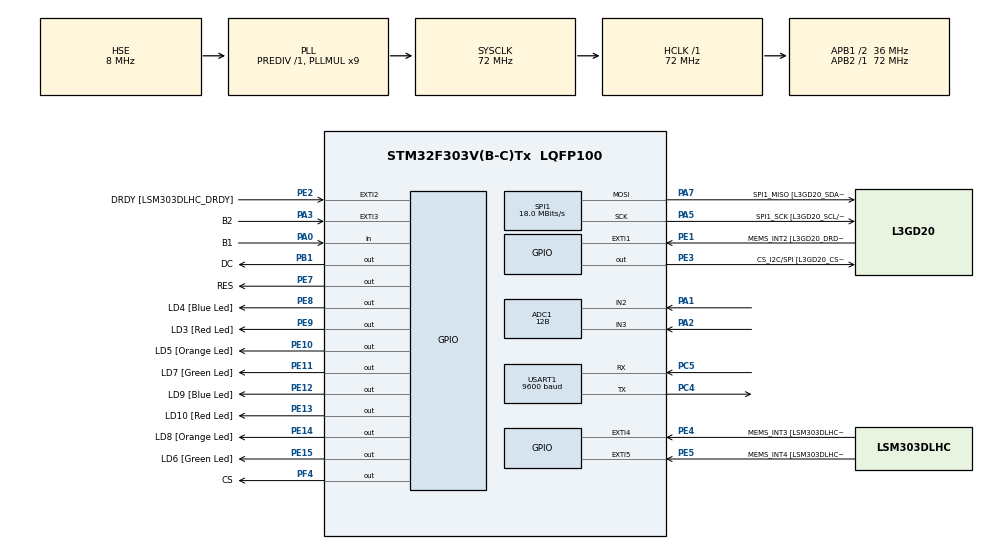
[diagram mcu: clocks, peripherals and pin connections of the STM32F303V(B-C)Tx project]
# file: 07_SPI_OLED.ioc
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ADC1.Channel-0\#ChannelRegularConversion=ADC_CHANNEL_2
ADC1.Channel-1\#ChannelRegularConversion=ADC_CHANNEL_3
ADC1.ClockPrescaler=ADC_CLOCK_ASYNC_DIV1
ADC1.ContinuousConvMode=ENABLE
ADC1.DMAContinuousRequests=ENABLE
ADC1.DataAlign=ADC_DATAALIGN_RIGHT
ADC1.DiscontinuousConvMode=DISABLE
ADC1.EOCSelection=ADC_EOC_SINGLE_CONV
ADC1.EnableAnalogWatchDog1=false
ADC1.EnableAnalogWatchDog2=false
ADC1.EnableAnalogWatchDog3=false
ADC1.EnableInjectedConversion=ENABLE
ADC1.EnableRegularConversion=ENABLE
ADC1.ExternalTrigConv=ADC_SOFTWARE_START
ADC1.ExternalTrigConvEdge=ADC_EXTERNALTRIGCONVEDGE_NONE
ADC1.InjNumberOfConversion=0
ADC1.LowPowerAutoWait=DISABLE
ADC1.NbrOfConversion=2
ADC1.NbrOfConversionFlag=1
ADC1.Offset-0\#ChannelRegularConversion=0
ADC1.Offset-1\#ChannelRegularConversion=0
ADC1.OffsetNumber-0\#ChannelRegularConversion=ADC_OFFSET_NONE
ADC1.OffsetNumber-1\#ChannelRegularConversion=ADC_OFFSET_NONE
ADC1.Overrun=ADC_OVR_DATA_OVERWRITTEN
ADC1.Rank-0\#ChannelRegularConversion=1
ADC1.Rank-1\#ChannelRegularConversion=2
ADC1.Resolution=ADC_RESOLUTION_12B
ADC1.SamplingTime-0\#ChannelRegularConversion=ADC_SAMPLETIME_181CYCLES_5
ADC1.SamplingTime-1\#ChannelRegularConversion=ADC_SAMPLETIME_181CYCLES_5
ADC1.ScanConvMode=ADC_SCAN_ENABLE
ADC1.master=1
Dma.ADC1.0.Direction=DMA_PERIPH_TO_MEMORY
Dma.ADC1.0.Instance=DMA1_Channel1
Dma.ADC1.0.MemDataAlignment=DMA_MDATAALIGN_HALFWORD
Dma.ADC1.0.MemInc=DMA_MINC_ENABLE
Dma.ADC1.0.Mode=DMA_CIRCULAR
Dma.ADC1.0.PeriphDataAlignment=DMA_PDATAALIGN_HALFWORD
Dma.ADC1.0.PeriphInc=DMA_PINC_DISABLE
Dma.ADC1.0.Priority=DMA_PRIORITY_LOW
Dma.Request0=ADC1
Mcu.Family=STM32F3
Mcu.Name=STM32F303V(B-C)Tx
Mcu.Package=LQFP100
NVIC.DMA1_Channel1_IRQn=true\:0\:0\:false\:false\:true\:false
NVIC.EXTI3_IRQn=true\:0\:0\:false\:false\:true\:true
NVIC.PriorityGroup=NVIC_PRIORITYGROUP_0
NVIC.TIM1_UP_TIM16_IRQn=true\:0\:0\:false\:false\:true\:true
NVIC.USART1_IRQn=true\:0\:0\:false\:false\:true\:true
PA0.GPIO_Label=B1
PA0.Signal=GPIO_Input
PA1.Mode=IN2-Single-Ended
PA1.Signal=ADC1_IN2
PA11.GPIO_Label=DM
PA11.Signal=USB_DM
PA12.GPIO_Label=DP
PA12.Signal=USB_DP
PA13.GPIO_Label=SWDIO
PA13.Signal=SYS_JTMS-SWDIO
PA14.GPIO_Label=SWCLK
PA14.Signal=SYS_JTCK-SWCLK
PA2.Mode=IN3-Single-Ended
PA2.Signal=ADC1_IN3
PA3.GPIO_Label=B2
PA3.GPIO_ModeDefaultEXTI=GPIO_MODE_IT_RISING_FALLING
PA3.GPIO_PuPd=GPIO_PULLUP
PA3.Signal=GPXTI3
PA5.GPIO_Label=SPI1_SCK [L3GD20_SCL/SPC]
PA5.GPIO_Mode=GPIO_MODE_AF_PP
PA5.GPIO_PuPd=GPIO_NOPULL
PA5.GPIO_Speed=GPIO_SPEED_FREQ_LOW
PA5.Mode=TX_Only_Simplex_Unidirect_Master
PA5.Signal=SPI1_SCK
PA6.GPIO_Label=SPI1_MISO [L3GD20_SA0/SDO]
PA6.GPIO_Mode=GPIO_MODE_AF_PP
PA6.GPIO_PuPd=GPIO_NOPULL
PA6.GPIO_Speed=GPIO_SPEED_FREQ_LOW
PA6.Signal=SPI1_MISO
PA7.GPIO_Label=SPI1_MISO [L3GD20_SDA/SDI/SDO]
PA7.GPIO_Mode=GPIO_MODE_AF_PP
PA7.GPIO_PuPd=GPIO_NOPULL
PA7.GPIO_Speed=GPIO_SPEED_FREQ_LOW
PA7.Mode=TX_Only_Simplex_Unidirect_Master
PA7.Signal=SPI1_MOSI
PB1.GPIO_Label=DC
PB1.Signal=GPIO_Output
PB3.GPIO_Label=SWO
PB3.Signal=SYS_JTDO-TRACESWO
PB6.GPIO_FM6=__NULL
PB6.GPIO_Label=I2C1_SCL [LSM303DLHC_SCL]
PB6.GPIO_Mode=GPIO_MODE_AF_OD
PB6.GPIO_PuPd=GPIO_NOPULL
PB6.GPIO_Speed=GPIO_SPEED_FREQ_LOW
PB6.Signal=I2C1_SCL
PB7.GPIO_FM7=__NULL
PB7.GPIO_Label=I2C1_SDA [LSM303DLHC_SDA]
PB7.GPIO_Mode=GPIO_MODE_AF_OD
PB7.GPIO_PuPd=GPIO_NOPULL
PB7.GPIO_Speed=GPIO_SPEED_FREQ_LOW
PB7.Signal=I2C1_SDA
PC14-OSC32_IN.GPIO_Label=OSC32_IN
PC14-OSC32_IN.Signal=RCC_OSC32_IN
PC15-OSC32_OUT.GPIO_Label=OSC32_OUT
PC15-OSC32_OUT.Signal=RCC_OSC32_OUT
PC4.GPIO_PuPd=GPIO_PULLUP
PC4.Mode=Asynchronous
PC4.Signal=USART1_TX
PC5.GPIO_PuPd=GPIO_PULLUP
PC5.Mode=Asynchronous
PC5.Signal=USART1_RX
PD6.Signal=USART2_RX
PE1.GPIO_Label=MEMS_INT2 [L3GD20_DRDY/INT2]
PE1.GPIO_ModeDefaultEXTI=GPIO_MODE_EVT_RISING
PE1.GPIO_PuPd=GPIO_NOPULL
PE1.Signal=GPXTI1
PE10.GPIO_Label=LD5 [Orange Led]
PE10.GPIO_ModeDefaultOutputPP=GPIO_MODE_OUTPUT_PP
PE10.GPIO_PuPd=GPIO_NOPULL
PE10.GPIO_Speed=GPIO_SPEED_FREQ_LOW
PE10.Signal=GPIO_Output
PE11.GPIO_Label=LD7 [Green Led]
PE11.GPIO_ModeDefaultOutputPP=GPIO_MODE_OUTPUT_PP
PE11.GPIO_PuPd=GPIO_NOPULL
PE11.GPIO_Speed=GPIO_SPEED_FREQ_LOW
PE11.Signal=GPIO_Output
PE12.GPIO_Label=LD9 [Blue Led]
PE12.GPIO_ModeDefaultOutputPP=GPIO_MODE_OUTPUT_PP
PE12.GPIO_PuPd=GPIO_NOPULL
PE12.GPIO_Speed=GPIO_SPEED_FREQ_LOW
PE12.Signal=GPIO_Output
PE13.GPIO_Label=LD10 [Red Led]
PE13.GPIO_ModeDefaultOutputPP=GPIO_MODE_OUTPUT_PP
PE13.GPIO_PuPd=GPIO_NOPULL
PE13.GPIO_Speed=GPIO_SPEED_FREQ_LOW
PE13.Signal=GPIO_Output
PE14.GPIO_Label=LD8 [Orange Led]
PE14.GPIO_ModeDefaultOutputPP=GPIO_MODE_OUTPUT_PP
PE14.GPIO_PuPd=GPIO_NOPULL
PE14.GPIO_Speed=GPIO_SPEED_FREQ_LOW
PE14.Signal=GPIO_Output
PE15.GPIO_Label=LD6 [Green Led]
PE15.GPIO_ModeDefaultOutputPP=GPIO_MODE_OUTPUT_PP
PE15.GPIO_PuPd=GPIO_NOPULL
PE15.GPIO_Speed=GPIO_SPEED_FREQ_LOW
PE15.Signal=GPIO_Output
PE2.GPIO_Label=DRDY [LSM303DLHC_DRDY]
PE2.GPIO_ModeDefaultEXTI=GPIO_MODE_EVT_RISING
PE2.GPIO_PuPd=GPIO_NOPULL
PE2.Signal=GPXTI2
PE3.GPIO_Label=CS_I2C/SPI [L3GD20_CS_I2C/SPI]
PE3.GPIO_ModeDefaultOutputPP=GPIO_MODE_OUTPUT_PP
PE3.GPIO_PuPd=GPIO_NOPULL
PE3.GPIO_Speed=GPIO_SPEED_FREQ_LOW
PE3.Signal=GPIO_Output
PE4.GPIO_Label=MEMS_INT3 [LSM303DLHC_INT1]
PE4.GPIO_ModeDefaultEXTI=GPIO_MODE_EVT_RISING
PE4.GPIO_PuPd=GPIO_NOPULL
PE4.Signal=GPXTI4
PE5.GPIO_Label=MEMS_INT4 [LSM303DLHC_INT2]
PE5.GPIO_ModeDefaultEXTI=GPIO_MODE_EVT_RISING
PE5.GPIO_PuPd=GPIO_NOPULL
PE5.Signal=GPXTI5
PE7.GPIO_Label=RES
PE7.Signal=GPIO_Output
PE8.GPIO_Label=LD4 [Blue Led]
PE8.GPIO_ModeDefaultOutputPP=GPIO_MODE_OUTPUT_PP
PE8.GPIO_PuPd=GPIO_NOPULL
PE8.GPIO_Speed=GPIO_SPEED_FREQ_LOW
PE8.Signal=GPIO_Output
PE9.GPIO_Label=LD3 [Red Led]
PE9.GPIO_ModeDefaultOutputPP=GPIO_MODE_OUTPUT_PP
PE9.GPIO_PuPd=GPIO_NOPULL
PE9.GPIO_Speed=GPIO_SPEED_FREQ_LOW
PE9.Signal=GPIO_Output
PF0-OSC_IN.GPIO_Label=OSC_IN
PF0-OSC_IN.Mode=HSE-External-Oscillator
PF0-OSC_IN.Signal=RCC_OSC_IN
PF1-OSC_OUT.GPIO_Label=OSC_OUT
PF1-OSC_OUT.Mode=HSE-External-Oscillator
PF1-OSC_OUT.Signal=RCC_OSC_OUT
PF4.GPIO_Label=CS
PF4.Signal=GPIO_Output
ProjectManager.HeapSize=0x200
ProjectManager.StackSize=0x400
ProjectManager.TargetToolchain=SW4STM32
RCC.AHBFreq_Value=72000000
RCC.APB1CLKDivider=RCC_HCLK_DIV2
RCC.APB1Freq_Value=36000000
RCC.APB1TimFreq_Value=72000000
RCC.APB2Freq_Value=72000000
RCC.APB2TimFreq_Value=72000000
RCC.CortexFreq_Value=72000000
RCC.HCLKFreq_Value=72000000
RCC.HSE_VALUE=8000000
RCC.HSI_VALUE=8000000
RCC.LSE_VALUE=32768
RCC.PLLMUL=RCC_PLL_MUL9
RCC.PLLSourceVirtual=RCC_PLLSOURCE_HSE
RCC.SYSCLKFreq_VALUE=72000000
RCC.SYSCLKSourceVirtual=RCC_SYSCLKSOURCE_PLLCLK
RCC.USBFreq_Value=72000000
SPI1.BaudRatePrescaler=SPI_BAUDRATEPRESCALER_4
SPI1.CLKPhase=SPI_PHASE_2EDGE
SPI1.CLKPolarity=SPI_POLARITY_HIGH
SPI1.CalculateBaudRate=18.0 MBits/s
SPI1.DataSize=SPI_DATASIZE_8BIT
SPI1.Direction=SPI_DIRECTION_2LINES
SPI1.Mode=SPI_MODE_MASTER
SPI1.VirtualType=VM_MASTER
TIM16.Period=3599
TIM16.Prescaler=9999
USART1.BaudRate=9600
USART1.VirtualMode-Asynchronous=VM_ASYNC
VP_TIM16_VS_ClockSourceINT.Mode=Enable_Timer
board=STM32F3DISCOVERY

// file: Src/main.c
/**
 ******************************************************************************
 * @file           : main.c
 * @brief          : Main program body
 ******************************************************************************
 ** This notice applies to any and all portions of this file
 * that are not between comment pairs USER CODE BEGIN and
 * USER CODE END. Other portions of this file, whether
 * inserted by the user or by software development tools
 * are owned by their respective copyright owners.
 *
 * COPYRIGHT(c) 2019 STMicroelectronics
 *
 * Redistribution and use in source and binary forms, with or without modification,
 * are permitted provided that the following conditions are met:
 *   1. Redistributions of source code must retain the above copyright notice,
 *      this list of conditions and the following disclaimer.
 *   2. Redistributions in binary form must reproduce the above copyright notice,
 *      this list of conditions and the following disclaimer in the documentation
 *      and/or other materials provided with the distribution.
 *   3. Neither the name of STMicroelectronics nor the names of its contributors
 *      may be used to endorse or promote products derived from this software
 *      without specific prior written permission.
 *
 * THIS SOFTWARE IS PROVIDED BY THE COPYRIGHT HOLDERS AND CONTRIBUTORS "AS IS"
 * AND ANY EXPRESS OR IMPLIED WARRANTIES, INCLUDING, BUT NOT LIMITED TO, THE
 * IMPLIED WARRANTIES OF MERCHANTABILITY AND FITNESS FOR A PARTICULAR PURPOSE ARE
 * DISCLAIMED. IN NO EVENT SHALL THE COPYRIGHT HOLDER OR CONTRIBUTORS BE LIABLE
 * FOR ANY DIRECT, INDIRECT, INCIDENTAL, SPECIAL, EXEMPLARY, OR CONSEQUENTIAL
 * DAMAGES (INCLUDING, BUT NOT LIMITED TO, PROCUREMENT OF SUBSTITUTE GOODS OR
 * SERVICES; LOSS OF USE, DATA, OR PROFITS; OR BUSINESS INTERRUPTION) HOWEVER
 * CAUSED AND ON ANY THEORY OF LIABILITY, WHETHER IN CONTRACT, STRICT LIABILITY,
 * OR TORT (INCLUDING NEGLIGENCE OR OTHERWISE) ARISING IN ANY WAY OUT OF THE USE
 * OF THIS SOFTWARE, EVEN IF ADVISED OF THE POSSIBILITY OF SUCH DAMAGE.
 *
 ******************************************************************************
 */
#include "main.h"
#include "stm32f3xx_hal.h"

/* USER CODE BEGIN Includes */
#include "SSD1331.h"

/* USER CODE END Includes */

ADC_HandleTypeDef hadc1;
DMA_HandleTypeDef hdma_adc1;

SPI_HandleTypeDef hspi1;

TIM_HandleTypeDef htim16;

UART_HandleTypeDef huart1;

/* USER CODE BEGIN PV */
/* Private variables ---------------------------------------------------------*/
volatile uint16_t Joystick[2];
uint8_t field[9];
uint8_t i;
uint8_t player = 0;
uint8_t win = 0;
uint8_t draw = 0;
uint8_t cursor = 0;
uint8_t move = 0;
uint8_t error = 0;
uint8_t scoreX = 0;
uint8_t scoreO = 0;
uint8_t Received;
uint8_t buffer[20];
uint8_t data[300]; // Tablica przechowujaca wysylana wiadomosc.
uint16_t size = 0; // Rozmiar wysylanej wiadomosci
/* USER CODE END PV */

void SystemClock_Config(void);
static void MX_GPIO_Init(void);
static void MX_DMA_Init(void);
static void MX_SPI1_Init(void);
static void MX_ADC1_Init(void);
static void MX_USART1_UART_Init(void);
static void MX_TIM16_Init(void);

/* USER CODE BEGIN PFP */
/* Private function prototypes -----------------------------------------------*/

static void drawOnScreen(bool gameInProgress) {
	uint16_t size = 0;
	char fieldChar[9];
	char currentPlayer;

	for (uint8_t i = 0; i < 9; i++) {
		if (field[i] == 0) {
			fieldChar[i] = 'X';
		} else if (field[i] == 1) {
			fieldChar[i] = 'O';
		} else if (field[i] == 2) {
			fieldChar[i] = ' ';
		} else {
			fieldChar[i] = ' ';
		}
	}

	if (player == 0 && gameInProgress == false) {
		currentPlayer = 'X';
	} else if (player == 1 && gameInProgress == false) {
		currentPlayer = 'O';
	} else if (player == 1 && gameInProgress == true) {
		currentPlayer = 'X';
	} else if (player == 0 && gameInProgress == true) {
		currentPlayer = 'O';
	}

	if (win == 1 && player == 0) {
		size =
				sprintf(data,
						"\n\r%c|%c|%c\n\r-+-+-\n\r%c|%c|%c\n\r-+-+-\n\r%c|%c|%c\n\r\n\r\n\r\x1b[31mGracz X wygral!\n\r",
						fieldChar[0], fieldChar[1], fieldChar[2], fieldChar[3],
						fieldChar[4], fieldChar[5], fieldChar[6], fieldChar[7],
						fieldChar[8], currentPlayer);
	} else if (win == 1 && player == 1) {
		size =
				sprintf(data,
						"\n\r%c|%c|%c\n\r-+-+-\n\r%c|%c|%c\n\r-+-+-\n\r%c|%c|%c\n\r\n\r\n\r\x1b[32mGracz O wygral!\n\r",
						fieldChar[0], fieldChar[1], fieldChar[2], fieldChar[3],
						fieldChar[4], fieldChar[5], fieldChar[6], fieldChar[7],
						fieldChar[8], currentPlayer);
	} else if (draw == 1) {
		size =
				sprintf(data,
						"\n\r%c|%c|%c\n\r-+-+-\n\r%c|%c|%c\n\r-+-+-\n\r%c|%c|%c\n\r\n\r\n\r\x1b[34mRemis!\n\r",
						fieldChar[0], fieldChar[1], fieldChar[2], fieldChar[3],
						fieldChar[4], fieldChar[5], fieldChar[6], fieldChar[7],
						fieldChar[8], currentPlayer);
	} else if (currentPlayer == 'X' && cursor == 0) {
		size =
				sprintf(data,
						"\n\r\x1b[31m%c|\x1b[0m%c|%c\n\r\x1b[31m-+\x1b[0m-+-\n\r%c|%c|%c\n\r-+-+-\n\r%c|%c|%c\n\r\n\r\x1b[31m\x1b[31mTura gracza %c!\n\r\x1b[0m\n\r",
						fieldChar[0], fieldChar[1], fieldChar[2], fieldChar[3],
						fieldChar[4], fieldChar[5], fieldChar[6], fieldChar[7],
						fieldChar[8], currentPlayer);
	} else if (currentPlayer == 'O' && cursor == 0) {
		size =
				sprintf(data,
						"\n\r\x1b[32m%c|\x1b[0m%c|%c\n\r\x1b[32m-+\x1b[0m-+-\n\r%c|%c|%c\n\r-+-+-\n\r%c|%c|%c\n\r\n\r\x1b[31m\x1b[32mTura gracza %c!\n\r\x1b[0m\n\r",
						fieldChar[0], fieldChar[1], fieldChar[2], fieldChar[3],
						fieldChar[4], fieldChar[5], fieldChar[6], fieldChar[7],
						fieldChar[8], currentPlayer);
	} else if (currentPlayer == 'X' && cursor == 1) {
		size =
				sprintf(data,
						"\x1b[0m\n\r%c\x1b[31m|%c|\x1b[0m%c\n\r-\x1b[31m+-+\x1b[0m-\n\r%c|%c|%c\n\r-+-+-\n\r%c|%c|%c\n\r\n\r\x1b[31mTura gracza %c!\n\r\x1b[0m\n\r",
						fieldChar[0], fieldChar[1], fieldChar[2], fieldChar[3],
						fieldChar[4], fieldChar[5], fieldChar[6], fieldChar[7],
						fieldChar[8], currentPlayer);
	} else if (currentPlayer == 'O' && cursor == 1) {
		size =
				sprintf(data,
						"\x1b[0m\n\r%c\x1b[32m|%c|\x1b[0m%c\n\r-\x1b[32m+-+\x1b[0m-\n\r%c|%c|%c\n\r-+-+-\n\r%c|%c|%c\n\r\n\r\x1b[32mTura gracza %c!\n\r\x1b[0m\n\r",
						fieldChar[0], fieldChar[1], fieldChar[2], fieldChar[3],
						fieldChar[4], fieldChar[5], fieldChar[6], fieldChar[7],
						fieldChar[8], currentPlayer);
	} else if (currentPlayer == 'X' && cursor == 2) {
		size =
				sprintf(data,
						"\x1b[0m\n\r%c|%c\x1b[31m|%c\x1b[0m\n\r-+-\x1b[31m+-\x1b[0m\n\r%c|%c|%c\n\r-+-+-\n\r%c|%c|%c\n\r\n\r\x1b[31mTura gracza %c!\n\r\x1b[0m\n\r",
						fieldChar[0], fieldChar[1], fieldChar[2], fieldChar[3],
						fieldChar[4], fieldChar[5], fieldChar[6], fieldChar[7],
						fieldChar[8], currentPlayer);
	} else if (currentPlayer == 'O' && cursor == 2) {
		size =
				sprintf(data,
						"\x1b[0m\n\r%c|%c\x1b[32m|%c\x1b[0m\n\r-+-\x1b[32m+-\x1b[0m\n\r%c|%c|%c\n\r-+-+-\n\r%c|%c|%c\n\r\n\r\x1b[32mTura gracza %c!\n\r\x1b[0m\n\r",
						fieldChar[0], fieldChar[1], fieldChar[2], fieldChar[3],
						fieldChar[4], fieldChar[5], fieldChar[6], fieldChar[7],
						fieldChar[8], currentPlayer);
	} else if (currentPlayer == 'X' && cursor == 3) {
		size =
				sprintf(data,
						"\x1b[0m\n\r%c|%c|%c\n\r\x1b[31m-+\x1b[0m-+-\n\r\x1b[31m%c|\x1b[0m%c|%c\n\r\x1b[31m-+\x1b[0m-+-\n\r%c|%c|%c\n\r\n\r\x1b[31mTura gracza %c!\n\r\x1b[0m\n\r",
						fieldChar[0], fieldChar[1], fieldChar[2], fieldChar[3],
						fieldChar[4], fieldChar[5], fieldChar[6], fieldChar[7],
						fieldChar[8], currentPlayer);
	} else if (currentPlayer == 'O' && cursor == 3) {
		size =
				sprintf(data,
						"\x1b[0m\n\r%c|%c|%c\n\r\x1b[32m-+\x1b[0m-+-\n\r\x1b[32m%c|\x1b[0m%c|%c\n\r\x1b[32m-+\x1b[0m-+-\n\r%c|%c|%c\n\r\n\r\x1b[32mTura gracza %c!\n\r\x1b[0m\n\r",
						fieldChar[0], fieldChar[1], fieldChar[2], fieldChar[3],
						fieldChar[4], fieldChar[5], fieldChar[6], fieldChar[7],
						fieldChar[8], currentPlayer);
	} else if (currentPlayer == 'X' && cursor == 4) {
		size =
				sprintf(data,
						"\x1b[0m\n\r%c|%c|%c\n\r-\x1b[31m+-+\x1b[0m-\n\r%c\x1b[31m|%c|\x1b[0m%c\n\r-\x1b[31m+-+\x1b[0m-\n\r%c|%c|%c\n\r\n\r\x1b[31mTura gracza %c!\n\r\x1b[0m\n\r",
						fieldChar[0], fieldChar[1], fieldChar[2], fieldChar[3],
						fieldChar[4], fieldChar[5], fieldChar[6], fieldChar[7],
						fieldChar[8], currentPlayer);
	} else if (currentPlayer == 'O' && cursor == 4) {
		size =
				sprintf(data,
						"\x1b[0m\n\r%c|%c|%c\n\r-\x1b[32m+-+\x1b[0m-\n\r%c\x1b[32m|%c|\x1b[0m%c\n\r-\x1b[32m+-+\x1b[0m-\n\r%c|%c|%c\n\r\n\r\x1b[32mTura gracza %c!\n\r\x1b[0m\n\r",
						fieldChar[0], fieldChar[1], fieldChar[2], fieldChar[3],
						fieldChar[4], fieldChar[5], fieldChar[6], fieldChar[7],
						fieldChar[8], currentPlayer);

	} else if (currentPlayer == 'X' && cursor == 5) {
		size =
				sprintf(data,
						"\x1b[0m\n\r%c|%c|%c\n\r-+-\x1b[31m+-\x1b[0m\n\r%c|%c\x1b[31m|%c\x1b[0m\n\r-+-\x1b[31m+-\x1b[0m\n\r%c|%c|%c\n\r\n\r\x1b[31mTura gracza %c!\n\r\x1b[0m\n\r",
						fieldChar[0], fieldChar[1], fieldChar[2], fieldChar[3],
						fieldChar[4], fieldChar[5], fieldChar[6], fieldChar[7],
						fieldChar[8], currentPlayer);
	} else if (currentPlayer == 'O' && cursor == 5) {
		size =
				sprintf(data,
						"\x1b[0m\n\r%c|%c|%c\n\r-+-\x1b[32m+-\x1b[0m\n\r%c|%c\x1b[32m|%c\x1b[0m\n\r-+-\x1b[32m+-\x1b[0m\n\r%c|%c|%c\n\r\n\r\x1b[32mTura gracza %c!\n\r\x1b[0m\n\r",
						fieldChar[0], fieldChar[1], fieldChar[2], fieldChar[3],
						fieldChar[4], fieldChar[5], fieldChar[6], fieldChar[7],
						fieldChar[8], currentPlayer);

	} else if (currentPlayer == 'X' && cursor == 6) {
		size =
				sprintf(data,
						"\x1b[0m\n\r%c|%c|%c\n\r-+-+-\n\r%c|%c|%c\n\r\x1b[31m-+\x1b[0m-+-\n\r\x1b[31m%c|\x1b[0m%c|%c\n\r\n\r\x1b[31mTura gracza %c!\n\r\x1b[0m\n\r",
						fieldChar[0], fieldChar[1], fieldChar[2], fieldChar[3],
						fieldChar[4], fieldChar[5], fieldChar[6], fieldChar[7],
						fieldChar[8], currentPlayer);
	} else if (currentPlayer == 'O' && cursor == 6) {
		size =
				sprintf(data,
						"\x1b[0m\n\r%c|%c|%c\n\r-+-+-\n\r%c|%c|%c\n\r\x1b[32m-+\x1b[0m-+-\n\r\x1b[32m%c|\x1b[0m%c|%c\n\r\n\r\x1b[32mTura gracza %c!\n\r\x1b[0m\n\r",
						fieldChar[0], fieldChar[1], fieldChar[2], fieldChar[3],
						fieldChar[4], fieldChar[5], fieldChar[6], fieldChar[7],
						fieldChar[8], currentPlayer);

	} else if (currentPlayer == 'X' && cursor == 7) {
		size =
				sprintf(data,
						"\x1b[0m\n\r%c|%c|%c\n\r-+-+-\n\r%c|%c|%c\n\r-\x1b[31m+-+\x1b[0m-\n\r%c\x1b[31m|%c|\x1b[0m%c\n\r\n\r\x1b[31mTura gracza %c!\n\r\x1b[0m\n\r",
						fieldChar[0], fieldChar[1], fieldChar[2], fieldChar[3],
						fieldChar[4], fieldChar[5], fieldChar[6], fieldChar[7],
						fieldChar[8], currentPlayer);
	} else if (currentPlayer == 'O' && cursor == 7) {
		size =
				sprintf(data,
						"\x1b[0m\n\r%c|%c|%c\n\r-+-+-\n\r%c|%c|%c\n\r-\x1b[32m+-+\x1b[0m-\n\r%c\x1b[32m|%c|\x1b[0m%c\n\r\n\r\x1b[32mTura gracza %c!\n\r\x1b[0m\n\r",
						fieldChar[0], fieldChar[1], fieldChar[2], fieldChar[3],
						fieldChar[4], fieldChar[5], fieldChar[6], fieldChar[7],
						fieldChar[8], currentPlayer);

	} else if (currentPlayer == 'X' && cursor == 8) {
		size =
				sprintf(data,
						"\x1b[0m\n\r%c|%c|%c\n\r-+-+-\n\r%c|%c|%c\n\r-+-\x1b[31m+-\x1b[0m\n\r%c|%c\x1b[31m|%c\x1b[0m\n\r\n\r\x1b[31mTura gracza %c!\n\r\x1b[0m\n\r",
						fieldChar[0], fieldChar[1], fieldChar[2], fieldChar[3],
						fieldChar[4], fieldChar[5], fieldChar[6], fieldChar[7],
						fieldChar[8], currentPlayer);
	} else if (currentPlayer == 'O' && cursor == 8) {
		size =
				sprintf(data,
						"\x1b[0m\n\r%c|%c|%c\n\r-+-+-\n\r%c|%c|%c\n\r-+-\x1b[32m+-\x1b[0m\n\r%c|%c\x1b[32m|%c\x1b[0m\n\r\n\r\x1b[32mTura gracza %c!\n\r\x1b[0m\n\r",
						fieldChar[0], fieldChar[1], fieldChar[2], fieldChar[3],
						fieldChar[4], fieldChar[5], fieldChar[6], fieldChar[7],
						fieldChar[8], currentPlayer);

	}
	HAL_UART_Transmit_IT(&huart1, data, size); // Rozpoczecie nadawania danych z wykorzystaniem przerwan
	HAL_GPIO_TogglePin(LD7_GPIO_Port, LD7_Pin); // Zmiana stanu pinu na diodzie LED

}

static void drawOnMove(bool gameInProgress) {
	uint16_t size = 0;
	char fieldChar[9];
	char currentPlayer;

	for (uint8_t i = 0; i < 9; i++) {
		if (field[i] == 0) {
			fieldChar[i] = 'X';
		} else if (field[i] == 1) {
			fieldChar[i] = 'O';
		} else if (field[i] == 2) {
			fieldChar[i] = ' ';
		} else {
			fieldChar[i] = ' ';
		}
	}

	if (player == 0 && gameInProgress == false) {
		currentPlayer = 'X';
	} else if (player == 1 && gameInProgress == false) {
		currentPlayer = 'O';
	} else if (player == 1 && gameInProgress == true) {
		currentPlayer = 'X';
	} else if (player == 0 && gameInProgress == true) {
		currentPlayer = 'O';
	}

	if (currentPlayer == 'X' && cursor == 0) {
		size =
				sprintf(data,
						"\n\r\x1b[31m%c|\x1b[0m%c|%c\n\r\x1b[31m-+\x1b[0m-+-\n\r%c|%c|%c\n\r-+-+-\n\r%c|%c|%c\n\r\n\r\x1b[31m\x1b[31mTura gracza %c!\n\r\x1b[0m\n\r",
						fieldChar[0], fieldChar[1], fieldChar[2], fieldChar[3],
						fieldChar[4], fieldChar[5], fieldChar[6], fieldChar[7],
						fieldChar[8], currentPlayer);
	} else if (currentPlayer == 'O' && cursor == 0) {
		size =
				sprintf(data,
						"\n\r\x1b[32m%c|\x1b[0m%c|%c\n\r\x1b[32m-+\x1b[0m-+-\n\r%c|%c|%c\n\r-+-+-\n\r%c|%c|%c\n\r\n\r\x1b[31m\x1b[32mTura gracza %c!\n\r\x1b[0m\n\r",
						fieldChar[0], fieldChar[1], fieldChar[2], fieldChar[3],
						fieldChar[4], fieldChar[5], fieldChar[6], fieldChar[7],
						fieldChar[8], currentPlayer);
	} else if (currentPlayer == 'X' && cursor == 1) {
		size =
				sprintf(data,
						"\x1b[0m\n\r%c\x1b[31m|%c|\x1b[0m%c\n\r-\x1b[31m+-+\x1b[0m-\n\r%c|%c|%c\n\r-+-+-\n\r%c|%c|%c\n\r\n\r\x1b[31mTura gracza %c!\n\r\x1b[0m\n\r",
						fieldChar[0], fieldChar[1], fieldChar[2], fieldChar[3],
						fieldChar[4], fieldChar[5], fieldChar[6], fieldChar[7],
						fieldChar[8], currentPlayer);
	} else if (currentPlayer == 'O' && cursor == 1) {
		size =
				sprintf(data,
						"\x1b[0m\n\r%c\x1b[32m|%c|\x1b[0m%c\n\r-\x1b[32m+-+\x1b[0m-\n\r%c|%c|%c\n\r-+-+-\n\r%c|%c|%c\n\r\n\r\x1b[32mTura gracza %c!\n\r\x1b[0m\n\r",
						fieldChar[0], fieldChar[1], fieldChar[2], fieldChar[3],
						fieldChar[4], fieldChar[5], fieldChar[6], fieldChar[7],
						fieldChar[8], currentPlayer);
	} else if (currentPlayer == 'X' && cursor == 2) {
		size =
				sprintf(data,
						"\x1b[0m\n\r%c|%c\x1b[31m|%c\x1b[0m\n\r-+-\x1b[31m+-\x1b[0m\n\r%c|%c|%c\n\r-+-+-\n\r%c|%c|%c\n\r\n\r\x1b[31mTura gracza %c!\n\r\x1b[0m\n\r",
						fieldChar[0], fieldChar[1], fieldChar[2], fieldChar[3],
						fieldChar[4], fieldChar[5], fieldChar[6], fieldChar[7],
						fieldChar[8], currentPlayer);
	} else if (currentPlayer == 'O' && cursor == 2) {
		size =
				sprintf(data,
						"\x1b[0m\n\r%c|%c\x1b[32m|%c\x1b[0m\n\r-+-\x1b[32m+-\x1b[0m\n\r%c|%c|%c\n\r-+-+-\n\r%c|%c|%c\n\r\n\r\x1b[32mTura gracza %c!\n\r\x1b[0m\n\r",
						fieldChar[0], fieldChar[1], fieldChar[2], fieldChar[3],
						fieldChar[4], fieldChar[5], fieldChar[6], fieldChar[7],
						fieldChar[8], currentPlayer);
	} else if (currentPlayer == 'X' && cursor == 3) {
		size =
				sprintf(data,
						"\x1b[0m\n\r%c|%c|%c\n\r\x1b[31m-+\x1b[0m-+-\n\r\x1b[31m%c|\x1b[0m%c|%c\n\r\x1b[31m-+\x1b[0m-+-\n\r%c|%c|%c\n\r\n\r\x1b[31mTura gracza %c!\n\r\x1b[0m\n\r",
						fieldChar[0], fieldChar[1], fieldChar[2], fieldChar[3],
						fieldChar[4], fieldChar[5], fieldChar[6], fieldChar[7],
						fieldChar[8], currentPlayer);
	} else if (currentPlayer == 'O' && cursor == 3) {
		size =
				sprintf(data,
						"\x1b[0m\n\r%c|%c|%c\n\r\x1b[32m-+\x1b[0m-+-\n\r\x1b[32m%c|\x1b[0m%c|%c\n\r\x1b[32m-+\x1b[0m-+-\n\r%c|%c|%c\n\r\n\r\x1b[32mTura gracza %c!\n\r\x1b[0m\n\r",
						fieldChar[0], fieldChar[1], fieldChar[2], fieldChar[3],
						fieldChar[4], fieldChar[5], fieldChar[6], fieldChar[7],
						fieldChar[8], currentPlayer);
	} else if (currentPlayer == 'X' && cursor == 4) {
		size =
				sprintf(data,
						"\x1b[0m\n\r%c|%c|%c\n\r-\x1b[31m+-+\x1b[0m-\n\r%c\x1b[31m|%c|\x1b[0m%c\n\r-\x1b[31m+-+\x1b[0m-\n\r%c|%c|%c\n\r\n\r\x1b[31mTura gracza %c!\n\r\x1b[0m\n\r",
						fieldChar[0], fieldChar[1], fieldChar[2], fieldChar[3],
						fieldChar[4], fieldChar[5], fieldChar[6], fieldChar[7],
						fieldChar[8], currentPlayer);
	} else if (currentPlayer == 'O' && cursor == 4) {
		size =
				sprintf(data,
						"\x1b[0m\n\r%c|%c|%c\n\r-\x1b[32m+-+\x1b[0m-\n\r%c\x1b[32m|%c|\x1b[0m%c\n\r-\x1b[32m+-+\x1b[0m-\n\r%c|%c|%c\n\r\n\r\x1b[32mTura gracza %c!\n\r\x1b[0m\n\r",
						fieldChar[0], fieldChar[1], fieldChar[2], fieldChar[3],
						fieldChar[4], fieldChar[5], fieldChar[6], fieldChar[7],
						fieldChar[8], currentPlayer);

	} else if (currentPlayer == 'X' && cursor == 5) {
		size =
				sprintf(data,
						"\x1b[0m\n\r%c|%c|%c\n\r-+-\x1b[31m+-\x1b[0m\n\r%c|%c\x1b[31m|%c\x1b[0m\n\r-+-\x1b[31m+-\x1b[0m\n\r%c|%c|%c\n\r\n\r\x1b[31mTura gracza %c!\n\r\x1b[0m\n\r",
						fieldChar[0], fieldChar[1], fieldChar[2], fieldChar[3],
						fieldChar[4], fieldChar[5], fieldChar[6], fieldChar[7],
						fieldChar[8], currentPlayer);
	} else if (currentPlayer == 'O' && cursor == 5) {
		size =
				sprintf(data,
						"\x1b[0m\n\r%c|%c|%c\n\r-+-\x1b[32m+-\x1b[0m\n\r%c|%c\x1b[32m|%c\x1b[0m\n\r-+-\x1b[32m+-\x1b[0m\n\r%c|%c|%c\n\r\n\r\x1b[32mTura gracza %c!\n\r\x1b[0m\n\r",
						fieldChar[0], fieldChar[1], fieldChar[2], fieldChar[3],
						fieldChar[4], fieldChar[5], fieldChar[6], fieldChar[7],
						fieldChar[8], currentPlayer);

	} else if (currentPlayer == 'X' && cursor == 6) {
		size =
				sprintf(data,
						"\x1b[0m\n\r%c|%c|%c\n\r-+-+-\n\r%c|%c|%c\n\r\x1b[31m-+\x1b[0m-+-\n\r\x1b[31m%c|\x1b[0m%c|%c\n\r\n\r\x1b[31mTura gracza %c!\n\r\x1b[0m\n\r",
						fieldChar[0], fieldChar[1], fieldChar[2], fieldChar[3],
						fieldChar[4], fieldChar[5], fieldChar[6], fieldChar[7],
						fieldChar[8], currentPlayer);
	} else if (currentPlayer == 'O' && cursor == 6) {
		size =
				sprintf(data,
						"\x1b[0m\n\r%c|%c|%c\n\r-+-+-\n\r%c|%c|%c\n\r\x1b[32m-+\x1b[0m-+-\n\r\x1b[32m%c|\x1b[0m%c|%c\n\r\n\r\x1b[32mTura gracza %c!\n\r\x1b[0m\n\r",
						fieldChar[0], fieldChar[1], fieldChar[2], fieldChar[3],
						fieldChar[4], fieldChar[5], fieldChar[6], fieldChar[7],
						fieldChar[8], currentPlayer);

	} else if (currentPlayer == 'X' && cursor == 7) {
		size =
				sprintf(data,
						"\x1b[0m\n\r%c|%c|%c\n\r-+-+-\n\r%c|%c|%c\n\r-\x1b[31m+-+\x1b[0m-\n\r%c\x1b[31m|%c|\x1b[0m%c\n\r\n\r\x1b[31mTura gracza %c!\n\r\x1b[0m\n\r",
						fieldChar[0], fieldChar[1], fieldChar[2], fieldChar[3],
						fieldChar[4], fieldChar[5], fieldChar[6], fieldChar[7],
						fieldChar[8], currentPlayer);
	} else if (currentPlayer == 'O' && cursor == 7) {
		size =
				sprintf(data,
						"\x1b[0m\n\r%c|%c|%c\n\r-+-+-\n\r%c|%c|%c\n\r-\x1b[32m+-+\x1b[0m-\n\r%c\x1b[32m|%c|\x1b[0m%c\n\r\n\r\x1b[32mTura gracza %c!\n\r\x1b[0m\n\r",
						fieldChar[0], fieldChar[1], fieldChar[2], fieldChar[3],
						fieldChar[4], fieldChar[5], fieldChar[6], fieldChar[7],
						fieldChar[8], currentPlayer);

	} else if (currentPlayer == 'X' && cursor == 8) {
		size =
				sprintf(data,
						"\x1b[0m\n\r%c|%c|%c\n\r-+-+-\n\r%c|%c|%c\n\r-+-\x1b[31m+-\x1b[0m\n\r%c|%c\x1b[31m|%c\x1b[0m\n\r\n\r\x1b[31mTura gracza %c!\n\r\x1b[0m\n\r",
						fieldChar[0], fieldChar[1], fieldChar[2], fieldChar[3],
						fieldChar[4], fieldChar[5], fieldChar[6], fieldChar[7],
						fieldChar[8], currentPlayer);
	} else if (currentPlayer == 'O' && cursor == 8) {
		size =
				sprintf(data,
						"\x1b[0m\n\r%c|%c|%c\n\r-+-+-\n\r%c|%c|%c\n\r-+-\x1b[32m+-\x1b[0m\n\r%c|%c\x1b[32m|%c\x1b[0m\n\r\n\r\x1b[32mTura gracza %c!\n\r\x1b[0m\n\r",
						fieldChar[0], fieldChar[1], fieldChar[2], fieldChar[3],
						fieldChar[4], fieldChar[5], fieldChar[6], fieldChar[7],
						fieldChar[8], currentPlayer);

	}
	HAL_UART_Transmit_IT(&huart1, data, size); // Rozpoczecie nadawania danych z wykorzystaniem przerwan
	HAL_GPIO_TogglePin(LD7_GPIO_Port, LD7_Pin); // Zmiana stanu pinu na diodzie LED

}

static void drawBoard() {
	ssd1331_draw_line(5, 20, 50, 20, PURPLE);
	ssd1331_draw_line(5, 35, 50, 35, PURPLE);
	ssd1331_draw_line(5, 50, 50, 50, PURPLE);
	ssd1331_draw_line(20, 5, 20, 50, PURPLE);
	ssd1331_draw_line(35, 5, 35, 50, PURPLE);
	ssd1331_draw_line(5, 5, 50, 5, PURPLE);
	ssd1331_draw_line(5, 5, 5, 50, PURPLE);
	ssd1331_draw_line(50, 5, 50, 50, PURPLE); //rysowanie planszy
}

static void writeScore() {
	ssd1331_display_string(55, 5, "Wynik:", FONT_1206, BROWN);
	ssd1331_display_string(55, 20, "X:", FONT_1206, BROWN);
	ssd1331_display_string(55, 35, "O:", FONT_1206, BROWN);
	if (scoreX >= 100) {
		ssd1331_display_num(70, 20, scoreX, 3, FONT_1206, BROWN);
	} else if (scoreX >= 10) {
		ssd1331_display_num(70, 20, scoreX, 2, FONT_1206, BROWN);
	} else if (scoreX < 10) {
		ssd1331_display_num(70, 20, scoreX, 1, FONT_1206, BROWN);
	}

	if (scoreO >= 100) {
		ssd1331_display_num(70, 35, scoreO, 3, FONT_1206, BROWN);
	} else if (scoreO >= 10) {
		ssd1331_display_num(70, 35, scoreO, 2, FONT_1206, BROWN);
	} else if (scoreO < 10) {
		ssd1331_display_num(70, 35, scoreO, 1, FONT_1206, BROWN);
	}

}

static void newGame() {
	HAL_Delay(2000);
	ssd1331_clear_screen(GREY);
	drawBoard();
	ssd1331_draw_line(5, 20, 20, 20, RED);
	ssd1331_draw_line(20, 5, 20, 20, RED);
	ssd1331_draw_line(5, 5, 5, 20, RED);
	ssd1331_draw_line(5, 5, 20, 5, RED); //poczatkowa pozycja kursora
	writeScore();
	win = 0;
	player = 0;
	cursor = 0;
	move = 0;
	draw = 0;
	for (i = 0; i < 9; i++) {
		field[i] = 2;
	}
	drawOnScreen(false);
}

static void checkWin() {
	if (player == 0) {
		if ((field[0] == 0 && field[1] == 0 && field[2] == 0)
				|| (field[3] == 0 && field[4] == 0 && field[5] == 0)
				|| (field[6] == 0 && field[7] == 0 && field[8] == 0)
				|| (field[0] == 0 && field[3] == 0 && field[6] == 0)
				|| (field[1] == 0 && field[4] == 0 && field[7] == 0)
				|| (field[2] == 0 && field[5] == 0 && field[8] == 0)
				|| (field[2] == 0 && field[4] == 0 && field[6] == 0)
				|| (field[0] == 0 && field[4] == 0 && field[8] == 0)) {
			win = 1;
			scoreX++;
			ssd1331_clear_screen(GREY);
			ssd1331_display_string(0, 0, "GRACZ X WYGRAL", FONT_1206, RED);
		}
	}
	if (player == 1) {
		if ((field[0] == 1 && field[1] == 1 && field[2] == 1)
				|| (field[3] == 1 && field[4] == 1 && field[5] == 1)
				|| (field[6] == 1 && field[7] == 1 && field[8] == 1)
				|| (field[0] == 1 && field[3] == 1 && field[6] == 1)
				|| (field[1] == 1 && field[4] == 1 && field[7] == 1)
				|| (field[2] == 1 && field[5] == 1 && field[8] == 1)
				|| (field[2] == 1 && field[4] == 1 && field[6] == 1)
				|| (field[0] == 1 && field[4] == 1 && field[8] == 1)) {
			win = 1;
			scoreO++;
			ssd1331_clear_screen(GREY);
			ssd1331_display_string(0, 0, "GRACZ O WYGRAL", FONT_1206, BROWN);
		}
	}
}

static void checkDraw() {
	if (field[0] != 2 && field[1] != 2 && field[2] != 2 && field[3] != 2
			&& field[4] != 2 && field[5] != 2 && field[6] != 2 && field[7] != 2
			&& field[8] != 2) {
		ssd1331_clear_screen(GREY);
		ssd1331_display_string(0, 0, "REMIS", FONT_1608, BLACK);
		draw = 1;
	}
}

static void drawCursor00() {
	drawBoard();
	ssd1331_draw_line(5, 20, 20, 20, RED);
	ssd1331_draw_line(20, 5, 20, 20, RED);
	ssd1331_draw_line(5, 5, 5, 20, RED);
	ssd1331_draw_line(5, 5, 20, 5, RED);
}

static void drawCursor10() {
	drawBoard();
	ssd1331_draw_line(35, 5, 35, 20, RED);
	ssd1331_draw_line(20, 20, 35, 20, RED);
	ssd1331_draw_line(20, 5, 20, 20, RED);
	ssd1331_draw_line(20, 5, 35, 5, RED);
}

static void drawCursor20() {
	drawBoard();
	ssd1331_draw_line(50, 5, 50, 20, RED);
	ssd1331_draw_line(35, 20, 50, 20, RED);
	ssd1331_draw_line(35, 5, 35, 20, RED);
	ssd1331_draw_line(35, 5, 50, 5, RED);
}

static void drawCursor30() {
	drawBoard();
	ssd1331_draw_line(5, 20, 20, 20, RED);
	ssd1331_draw_line(5, 20, 5, 35, RED);
	ssd1331_draw_line(5, 35, 20, 35, RED);
	ssd1331_draw_line(20, 20, 20, 35, RED);
}

static void drawCursor40() {
	drawBoard();
	ssd1331_draw_line(20, 20, 35, 20, RED);
	ssd1331_draw_line(20, 20, 20, 35, RED);
	ssd1331_draw_line(20, 35, 35, 35, RED);
	ssd1331_draw_line(35, 20, 35, 35, RED);
}

static void drawCursor50() {
	drawBoard();
	ssd1331_draw_line(35, 20, 50, 20, RED);
	ssd1331_draw_line(35, 20, 35, 35, RED);
	ssd1331_draw_line(35, 35, 50, 35, RED);
	ssd1331_draw_line(50, 20, 50, 35, RED);
}

static void drawCursor60() {
	drawBoard();
	ssd1331_draw_line(5, 35, 5, 50, RED);
	ssd1331_draw_line(5, 35, 20, 35, RED);
	ssd1331_draw_line(5, 50, 20, 50, RED);
	ssd1331_draw_line(20, 35, 20, 50, RED);
}

static void drawCursor70() {
	drawBoard();
	ssd1331_draw_line(20, 35, 35, 35, RED);
	ssd1331_draw_line(20, 35, 20, 50, RED);
	ssd1331_draw_line(20, 50, 35, 50, RED);
	ssd1331_draw_line(35, 35, 35, 50, RED);
}

static void drawCursor80() {
	drawBoard();
	ssd1331_draw_line(35, 35, 50, 35, RED);
	ssd1331_draw_line(35, 35, 35, 50, RED);
	ssd1331_draw_line(35, 50, 50, 50, RED);
	ssd1331_draw_line(50, 35, 50, 50, RED);
}

static void drawCursor01() {
	drawBoard();
	ssd1331_draw_line(5, 20, 20, 20, GREEN);
	ssd1331_draw_line(20, 5, 20, 20, GREEN);
	ssd1331_draw_line(5, 5, 5, 20, GREEN);
	ssd1331_draw_line(5, 5, 20, 5, GREEN);
}

static void drawCursor11() {
	drawBoard();
	ssd1331_draw_line(35, 5, 35, 20, GREEN);
	ssd1331_draw_line(20, 20, 35, 20, GREEN);
	ssd1331_draw_line(20, 5, 20, 20, GREEN);
	ssd1331_draw_line(20, 5, 35, 5, GREEN);
}

static void drawCursor21() {
	drawBoard();
	ssd1331_draw_line(50, 5, 50, 20, GREEN);
	ssd1331_draw_line(35, 20, 50, 20, GREEN);
	ssd1331_draw_line(35, 5, 35, 20, GREEN);
	ssd1331_draw_line(35, 5, 50, 5, GREEN);
}

static void drawCursor31() {
	drawBoard();
	ssd1331_draw_line(5, 20, 20, 20, GREEN);
	ssd1331_draw_line(5, 20, 5, 35, GREEN);
	ssd1331_draw_line(5, 35, 20, 35, GREEN);
	ssd1331_draw_line(20, 20, 20, 35, GREEN);
}

static void drawCursor41() {
	drawBoard();
	ssd1331_draw_line(20, 20, 35, 20, GREEN);
	ssd1331_draw_line(20, 20, 20, 35, GREEN);
	ssd1331_draw_line(20, 35, 35, 35, GREEN);
	ssd1331_draw_line(35, 20, 35, 35, GREEN);
}

static void drawCursor51() {
	drawBoard();
	ssd1331_draw_line(35, 20, 50, 20, GREEN);
	ssd1331_draw_line(35, 20, 35, 35, GREEN);
	ssd1331_draw_line(35, 35, 50, 35, GREEN);
	ssd1331_draw_line(50, 20, 50, 35, GREEN);
}

static void drawCursor61() {
	drawBoard();
	ssd1331_draw_line(5, 35, 5, 50, GREEN);
	ssd1331_draw_line(5, 35, 20, 35, GREEN);
	ssd1331_draw_line(5, 50, 20, 50, GREEN);
	ssd1331_draw_line(20, 35, 20, 50, GREEN);
}

static void drawCursor71() {
	drawBoard();
	ssd1331_draw_line(20, 35, 35, 35, GREEN);
	ssd1331_draw_line(20, 35, 20, 50, GREEN);
	ssd1331_draw_line(20, 50, 35, 50, GREEN);
	ssd1331_draw_line(35, 35, 35, 50, GREEN);
}

static void drawCursor81() {
	drawBoard();
	ssd1331_draw_line(35, 35, 50, 35, GREEN);
	ssd1331_draw_line(35, 35, 35, 50, GREEN);
	ssd1331_draw_line(35, 50, 50, 50, GREEN);
	ssd1331_draw_line(50, 35, 50, 50, GREEN);
}

static void moveCursorOnScreen() {
	if (player == 0) {

		if (cursor == 0) {
			drawCursor00();

		} else if (cursor == 1) {
			drawCursor10();

		} else if (cursor == 2) {
			drawCursor20();

		} else if (cursor == 3) {
			drawCursor30();

		} else if (cursor == 4) {
			drawCursor40();

		} else if (cursor == 5) {
			drawCursor50();

		} else if (cursor == 6) {
			drawCursor60();

		} else if (cursor == 7) {
			drawCursor70();

		} else if (cursor == 8) {
			drawCursor80();

		}
	} else {
		if (cursor == 0) {
			drawCursor01();

		} else if (cursor == 1) {
			drawCursor11();

		} else if (cursor == 2) {
			drawCursor21();

		} else if (cursor == 3) {
			drawCursor31();

		} else if (cursor == 4) {
			drawCursor41();

		} else if (cursor == 5) {
			drawCursor51();

		} else if (cursor == 6) {
			drawCursor61();

		} else if (cursor == 7) {
			drawCursor71();

		} else if (cursor == 8) {
			drawCursor81();

		}
	}
	drawOnMove(false);
}

static void insert() {
	if (player == 0) {
		if (cursor == 0) {
			if (field[0] == 2) {
				field[0] = 0;
				ssd1331_display_string(8, 5, "X", FONT_1608, BLACK);
				drawCursor01();
				checkWin();
				if (win == 1) {

				} else
					checkDraw();
			} else
				error = 1;
		} else if (cursor == 1) {
			if (field[1] == 2) {

				field[1] = 0;
				ssd1331_display_string(23, 5, "X", FONT_1608, BLACK);
				drawCursor11();
				checkWin();
				if (win == 1) {

				} else
					checkDraw();

			} else
				error = 1;
		}

		else if (cursor == 2) {
			if (field[2] == 2) {

				field[2] = 0;
				ssd1331_display_string(38, 5, "X", FONT_1608, BLACK);
				drawCursor21();
				checkWin();
				if (win == 1) {

				} else
					checkDraw();
			} else
				error = 1;

		}

		else if (cursor == 3) {
			if (field[3] == 2) {

				field[3] = 0;
				ssd1331_display_string(8, 20, "X", FONT_1608, BLACK);
				drawCursor31();
				checkWin();
				if (win == 1) {

				} else
					checkDraw();
			} else
				error = 1;

		}

		else if (cursor == 4) {
			if (field[4] == 2) {

				field[4] = 0;
				ssd1331_display_string(23, 20, "X", FONT_1608, BLACK);
				drawCursor41();
				checkWin();
				if (win == 1) {

				} else
					checkDraw();
			} else
				error = 1;

		}

		else if (cursor == 5) {
			if (field[5] == 2) {

				field[5] = 0;
				ssd1331_display_string(38, 20, "X", FONT_1608, BLACK);
				drawCursor51();
				checkWin();
				if (win == 1) {

				} else
					checkDraw();
			} else
				error = 1;

		}

		else if (cursor == 6) {
			if (field[6] == 2) {

				field[6] = 0;
				ssd1331_display_string(8, 35, "X", FONT_1608, BLACK);
				drawCursor61();
				checkWin();
				if (win == 1) {

				} else
					checkDraw();
			} else
				error = 1;

		}

		else if (cursor == 7) {
			if (field[7] == 2) {

				field[7] = 0;
				ssd1331_display_string(23, 35, "X", FONT_1608, BLACK);
				drawCursor71();
				checkWin();
				if (win == 1) {

				} else
					checkDraw();
			} else
				error = 1;

		}

		else if (cursor == 8) {
			if (field[8] == 2) {

				field[8] = 0;
				ssd1331_display_string(38, 35, "X", FONT_1608, BLACK);
				drawCursor81();
				checkWin();
				if (win == 1) {

				} else
					checkDraw();
			} else
				error = 1;

		}

	} else if (player == 1) {
		if (cursor == 0) {
			if (field[0] == 2) {
				field[0] = 1;
				ssd1331_display_string(8, 5, "O", FONT_1608, BLACK);
				drawCursor00();
				checkWin();
				if (win == 1) {

				} else
					checkDraw();
			} else
				error = 1;

		} else if (cursor == 1) {
			if (field[1] == 2) {
				field[1] = 1;
				ssd1331_display_string(23, 5, "O", FONT_1608, BLACK);
				drawCursor10();
				checkWin();
				if (win == 1) {

				} else
					checkDraw();
			} else
				error = 1;

		}

		else if (cursor == 2) {
			if (field[2] == 2) {
				field[2] = 1;
				ssd1331_display_string(38, 5, "O", FONT_1608, BLACK);
				drawCursor20();
				checkWin();
				if (win == 1) {

				} else
					checkDraw();
			} else
				error = 1;

		}

		else if (cursor == 3) {
			if (field[3] == 2) {
				field[3] = 1;
				ssd1331_display_string(8, 20, "O", FONT_1608, BLACK);
				drawCursor30();
				checkWin();
				if (win == 1) {

				} else
					checkDraw();
			} else
				error = 1;

		}

		else if (cursor == 4) {
			if (field[4] == 2) {
				field[4] = 1;
				ssd1331_display_string(23, 20, "O", FONT_1608, BLACK);
				drawCursor40();
				checkWin();
				if (win == 1) {

				} else
					checkDraw();
			} else
				error = 1;

		}

		else if (cursor == 5) {
			if (field[5] == 2) {
				field[5] = 1;
				ssd1331_display_string(38, 20, "O", FONT_1608, BLACK);
				drawCursor50();
				checkWin();
				if (win == 1) {

				} else
					checkDraw();
			} else
				error = 1;

		}

		else if (cursor == 6) {
			if (field[6] == 2) {
				field[6] = 1;
				ssd1331_display_string(8, 35, "O", FONT_1608, BLACK);
				drawCursor60();
				checkWin();
				if (win == 1) {

				} else
					checkDraw();
			} else
				error = 1;

		}

		else if (cursor == 7) {
			if (field[7] == 2) {
				field[7] = 1;
				ssd1331_display_string(23, 35, "O", FONT_1608, BLACK);
				drawCursor70();
				checkWin();
				if (win == 1) {

				} else
					checkDraw();
			} else
				error = 1;

		}

		else if (cursor == 8) {
			if (field[8] == 2) {
				field[8] = 1;
				ssd1331_display_string(38, 35, "O", FONT_1608, BLACK);
				drawCursor80();
				checkWin();
				if (win == 1) {

				} else
					checkDraw();
			} else
				error = 1;

		}

	}
	if (error == 0) {
		drawOnScreen(true);
		if (player == 0)
			player = 1;
		else
			player = 0;
	} else {
		error = 0;
	}

	HAL_Delay(500);
	move = 0;
	if (win == 1 || draw == 1) {
		newGame();
	}

}

static void displayScoreboard() {
	uint16_t size = 0;

	size = sprintf(data,
			"\n\rWynik:\n\r\x1b[31mX: %d\n\r\x1b[32mO: %d\x1b[0m\n\r", scoreX,
			scoreO);

	HAL_UART_Transmit_IT(&huart1, data, size); // Rozpoczecie nadawania danych z wykorzystaniem przerwan
	HAL_GPIO_TogglePin(LD7_GPIO_Port, LD7_Pin); // Zmiana stanu pinu na diodzie LED

}

void HAL_GPIO_EXTI_Callback(uint16_t GPIO_Pin) {

	move = 1;
}

/* USER CODE END PFP */

int main(void) {

	/* MCU Configuration----------------------------------------------------------*/

	/* Reset of all peripherals, Initializes the Flash interface and the Systick. */
	HAL_Init();

	/* Configure the system clock */
	SystemClock_Config();

	/* Initialize all configured peripherals */
	MX_GPIO_Init();
	MX_DMA_Init();
	MX_SPI1_Init();
	MX_ADC1_Init();
	MX_USART1_UART_Init();
	MX_TIM16_Init();
	/* USER CODE BEGIN 2 */
	HAL_TIM_Base_Start_IT(&htim16);
	HAL_UART_Receive_IT(&huart1, &Received, 1);
	HAL_ADC_Start_DMA(&hadc1, (uint32_t*) Joystick, 2);

	size =
			sprintf(data,
					"Sterowanie:\n\rw - kursor w gore\n\rs - kursor w dol\n\ra - kursor w lewo\n\rd - kursor w prawo\n\rf - zajmij pole\n\rg - pokaz tablice wynikow\n\r ");

	HAL_UART_Transmit_IT(&huart1, data, size); // Rozpoczecie nadawania danych z wykorzystaniem przerwan
	ssd1331_init();
	ssd1331_clear_screen(GREY);
	drawBoard();
	ssd1331_draw_line(5, 20, 20, 20, RED);
	ssd1331_draw_line(20, 5, 20, 20, RED);
	ssd1331_draw_line(5, 5, 5, 20, RED);
	ssd1331_draw_line(5, 5, 20, 5, RED); //poczatkowa pozycja kursora
	writeScore();
	for (i = 0; i < 9; i++) {
		field[i] = 2;
	}
	drawOnScreen(false);

	/* USER CODE END 2 */

	/* Infinite loop */
	/* USER CODE BEGIN WHILE */
	while (1) {
		buffer[0] = 0;
		HAL_UART_Receive(&huart1, buffer, 20, 100);
		if (buffer[0] == 'w') {
			if (cursor >= 3) {
				cursor -= 3;
				moveCursorOnScreen();
			}
			HAL_GPIO_TogglePin(LD10_GPIO_Port, LD10_Pin);
		} else if (buffer[0] == 's') {
			if (cursor <= 5) {
				cursor += 3;
				moveCursorOnScreen();
			}
			HAL_GPIO_TogglePin(LD10_GPIO_Port, LD10_Pin);
		} else if (buffer[0] == 'a') {
			if (cursor != 0 && cursor != 3 && cursor != 6) {
				cursor -= 1;
				moveCursorOnScreen();
			}
			HAL_GPIO_TogglePin(LD10_GPIO_Port, LD10_Pin);
		} else if (buffer[0] == 'd') {
			if (cursor != 2 && cursor != 5 && cursor != 8) {
				cursor += 1;
				moveCursorOnScreen();
			}
			HAL_GPIO_TogglePin(LD10_GPIO_Port, LD10_Pin);
		} else if (buffer[0] == 'f') {
			insert();
		} else if (buffer[0] == 'g') {
			displayScoreboard();
		}

		/* USER CODE END WHILE */

		/* USER CODE BEGIN 3 */

		if (move == 1) {
			insert();

		}

		if (Joystick[0] > 3500) {
			if (cursor != 8) {
				cursor++;
			} else
				cursor = 0;

			moveCursorOnScreen();
			HAL_Delay(500);
		}
		if (Joystick[0] < 500) {
			if (cursor != 0) {
				cursor--;
			} else
				cursor = 8;

			moveCursorOnScreen();
			HAL_Delay(500);

		}

	}
	/* USER CODE END 3 */

}

void SystemClock_Config(void) {

	RCC_OscInitTypeDef RCC_OscInitStruct;
	RCC_ClkInitTypeDef RCC_ClkInitStruct;
	RCC_PeriphCLKInitTypeDef PeriphClkInit;

	/**Initializes the CPU, AHB and APB busses clocks
	 */
	RCC_OscInitStruct.OscillatorType = RCC_OSCILLATORTYPE_HSE;
	RCC_OscInitStruct.HSEState = RCC_HSE_ON;
	RCC_OscInitStruct.HSEPredivValue = RCC_HSE_PREDIV_DIV1;
	RCC_OscInitStruct.HSIState = RCC_HSI_ON;
	RCC_OscInitStruct.PLL.PLLState = RCC_PLL_ON;
	RCC_OscInitStruct.PLL.PLLSource = RCC_PLLSOURCE_HSE;
	RCC_OscInitStruct.PLL.PLLMUL = RCC_PLL_MUL9;
	if (HAL_RCC_OscConfig(&RCC_OscInitStruct) != HAL_OK) {
		_Error_Handler(__FILE__, __LINE__);
	}

	/**Initializes the CPU, AHB and APB busses clocks
	 */
	RCC_ClkInitStruct.ClockType = RCC_CLOCKTYPE_HCLK | RCC_CLOCKTYPE_SYSCLK
			| RCC_CLOCKTYPE_PCLK1 | RCC_CLOCKTYPE_PCLK2;
	RCC_ClkInitStruct.SYSCLKSource = RCC_SYSCLKSOURCE_PLLCLK;
	RCC_ClkInitStruct.AHBCLKDivider = RCC_SYSCLK_DIV1;
	RCC_ClkInitStruct.APB1CLKDivider = RCC_HCLK_DIV2;
	RCC_ClkInitStruct.APB2CLKDivider = RCC_HCLK_DIV1;

	if (HAL_RCC_ClockConfig(&RCC_ClkInitStruct, FLASH_LATENCY_2) != HAL_OK) {
		_Error_Handler(__FILE__, __LINE__);
	}

	PeriphClkInit.PeriphClockSelection = RCC_PERIPHCLK_USART1
			| RCC_PERIPHCLK_ADC12;
	PeriphClkInit.Usart1ClockSelection = RCC_USART1CLKSOURCE_PCLK2;
	PeriphClkInit.Adc12ClockSelection = RCC_ADC12PLLCLK_DIV1;
	if (HAL_RCCEx_PeriphCLKConfig(&PeriphClkInit) != HAL_OK) {
		_Error_Handler(__FILE__, __LINE__);
	}

	/**Configure the Systick interrupt time
	 */
	HAL_SYSTICK_Config(HAL_RCC_GetHCLKFreq() / 1000);

	/**Configure the Systick
	 */
	HAL_SYSTICK_CLKSourceConfig(SYSTICK_CLKSOURCE_HCLK);

	/* SysTick_IRQn interrupt configuration */
	HAL_NVIC_SetPriority(SysTick_IRQn, 0, 0);
}

/* ADC1 init function */
static void MX_ADC1_Init(void) {

	ADC_MultiModeTypeDef multimode;
	ADC_ChannelConfTypeDef sConfig;

	/**Common config
	 */
	hadc1.Instance = ADC1;
	hadc1.Init.ClockPrescaler = ADC_CLOCK_ASYNC_DIV1;
	hadc1.Init.Resolution = ADC_RESOLUTION_12B;
	hadc1.Init.ScanConvMode = ADC_SCAN_ENABLE;
	hadc1.Init.ContinuousConvMode = ENABLE;
	hadc1.Init.DiscontinuousConvMode = DISABLE;
	hadc1.Init.ExternalTrigConvEdge = ADC_EXTERNALTRIGCONVEDGE_NONE;
	hadc1.Init.ExternalTrigConv = ADC_SOFTWARE_START;
	hadc1.Init.DataAlign = ADC_DATAALIGN_RIGHT;
	hadc1.Init.NbrOfConversion = 2;
	hadc1.Init.DMAContinuousRequests = ENABLE;
	hadc1.Init.EOCSelection = ADC_EOC_SINGLE_CONV;
	hadc1.Init.LowPowerAutoWait = DISABLE;
	hadc1.Init.Overrun = ADC_OVR_DATA_OVERWRITTEN;
	if (HAL_ADC_Init(&hadc1) != HAL_OK) {
		_Error_Handler(__FILE__, __LINE__);
	}

	/**Configure the ADC multi-mode
	 */
	multimode.Mode = ADC_MODE_INDEPENDENT;
	if (HAL_ADCEx_MultiModeConfigChannel(&hadc1, &multimode) != HAL_OK) {
		_Error_Handler(__FILE__, __LINE__);
	}

	/**Configure Regular Channel
	 */
	sConfig.Channel = ADC_CHANNEL_2;
	sConfig.Rank = ADC_REGULAR_RANK_1;
	sConfig.SingleDiff = ADC_SINGLE_ENDED;
	sConfig.SamplingTime = ADC_SAMPLETIME_181CYCLES_5;
	sConfig.OffsetNumber = ADC_OFFSET_NONE;
	sConfig.Offset = 0;
	if (HAL_ADC_ConfigChannel(&hadc1, &sConfig) != HAL_OK) {
		_Error_Handler(__FILE__, __LINE__);
	}

	/**Configure Regular Channel
	 */
	sConfig.Channel = ADC_CHANNEL_3;
	sConfig.Rank = ADC_REGULAR_RANK_2;
	if (HAL_ADC_ConfigChannel(&hadc1, &sConfig) != HAL_OK) {
		_Error_Handler(__FILE__, __LINE__);
	}

}

/* SPI1 init function */
static void MX_SPI1_Init(void) {

	/* SPI1 parameter configuration*/
	hspi1.Instance = SPI1;
	hspi1.Init.Mode = SPI_MODE_MASTER;
	hspi1.Init.Direction = SPI_DIRECTION_2LINES;
	hspi1.Init.DataSize = SPI_DATASIZE_8BIT;
	hspi1.Init.CLKPolarity = SPI_POLARITY_HIGH;
	hspi1.Init.CLKPhase = SPI_PHASE_2EDGE;
	hspi1.Init.NSS = SPI_NSS_SOFT;
	hspi1.Init.BaudRatePrescaler = SPI_BAUDRATEPRESCALER_4;
	hspi1.Init.FirstBit = SPI_FIRSTBIT_MSB;
	hspi1.Init.TIMode = SPI_TIMODE_DISABLE;
	hspi1.Init.CRCCalculation = SPI_CRCCALCULATION_DISABLE;
	hspi1.Init.CRCPolynomial = 7;
	hspi1.Init.CRCLength = SPI_CRC_LENGTH_DATASIZE;
	hspi1.Init.NSSPMode = SPI_NSS_PULSE_DISABLE;
	if (HAL_SPI_Init(&hspi1) != HAL_OK) {
		_Error_Handler(__FILE__, __LINE__);
	}

}

/* TIM16 init function */
static void MX_TIM16_Init(void) {

	htim16.Instance = TIM16;
	htim16.Init.Prescaler = 9999;
	htim16.Init.CounterMode = TIM_COUNTERMODE_UP;
	htim16.Init.Period = 3599;
	htim16.Init.ClockDivision = TIM_CLOCKDIVISION_DIV1;
	htim16.Init.RepetitionCounter = 0;
	htim16.Init.AutoReloadPreload = TIM_AUTORELOAD_PRELOAD_DISABLE;
	if (HAL_TIM_Base_Init(&htim16) != HAL_OK) {
		_Error_Handler(__FILE__, __LINE__);
	}

}

/* USART1 init function */
static void MX_USART1_UART_Init(void) {

	huart1.Instance = USART1;
	huart1.Init.BaudRate = 9600;
	huart1.Init.WordLength = UART_WORDLENGTH_8B;
	huart1.Init.StopBits = UART_STOPBITS_1;
	huart1.Init.Parity = UART_PARITY_NONE;
	huart1.Init.Mode = UART_MODE_TX_RX;
	huart1.Init.HwFlowCtl = UART_HWCONTROL_NONE;
	huart1.Init.OverSampling = UART_OVERSAMPLING_16;
	huart1.Init.OneBitSampling = UART_ONE_BIT_SAMPLE_DISABLE;
	huart1.AdvancedInit.AdvFeatureInit = UART_ADVFEATURE_NO_INIT;
	if (HAL_UART_Init(&huart1) != HAL_OK) {
		_Error_Handler(__FILE__, __LINE__);
	}

}

static void MX_DMA_Init(void) {
	/* DMA controller clock enable */
	__HAL_RCC_DMA1_CLK_ENABLE()
	;

	/* DMA interrupt init */
	/* DMA1_Channel1_IRQn interrupt configuration */
	HAL_NVIC_SetPriority(DMA1_Channel1_IRQn, 0, 0);
	HAL_NVIC_EnableIRQ(DMA1_Channel1_IRQn);

}

/** Configure pins as
 * Analog
 * Input
 * Output
 * EVENT_OUT
 * EXTI
 PA11   ------> USB_DM
 PA12   ------> USB_DP
 PD6   ------> USART2_RX
 PB6   ------> I2C1_SCL
 PB7   ------> I2C1_SDA
 */
static void MX_GPIO_Init(void) {

	GPIO_InitTypeDef GPIO_InitStruct;

	/* GPIO Ports Clock Enable */
	__HAL_RCC_GPIOE_CLK_ENABLE()
	;
	__HAL_RCC_GPIOC_CLK_ENABLE()
	;
	__HAL_RCC_GPIOF_CLK_ENABLE()
	;
	__HAL_RCC_GPIOA_CLK_ENABLE()
	;
	__HAL_RCC_GPIOB_CLK_ENABLE()
	;
	__HAL_RCC_GPIOD_CLK_ENABLE()
	;

	/*Configure GPIO pin Output Level */
	HAL_GPIO_WritePin(GPIOE,
			CS_I2C_SPI_Pin | RES_Pin | LD4_Pin | LD3_Pin | LD5_Pin | LD7_Pin
					| LD9_Pin | LD10_Pin | LD8_Pin | LD6_Pin, GPIO_PIN_RESET);

	/*Configure GPIO pin Output Level */
	HAL_GPIO_WritePin(CS_GPIO_Port, CS_Pin, GPIO_PIN_RESET);

	/*Configure GPIO pin Output Level */
	HAL_GPIO_WritePin(DC_GPIO_Port, DC_Pin, GPIO_PIN_RESET);

	/*Configure GPIO pins : DRDY_Pin MEMS_INT3_Pin MEMS_INT4_Pin MEMS_INT2_Pin */
	GPIO_InitStruct.Pin = DRDY_Pin | MEMS_INT3_Pin | MEMS_INT4_Pin
			| MEMS_INT2_Pin;
	GPIO_InitStruct.Mode = GPIO_MODE_EVT_RISING;
	GPIO_InitStruct.Pull = GPIO_NOPULL;
	HAL_GPIO_Init(GPIOE, &GPIO_InitStruct);

	/*Configure GPIO pins : CS_I2C_SPI_Pin RES_Pin LD4_Pin LD3_Pin
	 LD5_Pin LD7_Pin LD9_Pin LD10_Pin
	 LD8_Pin LD6_Pin */
	GPIO_InitStruct.Pin = CS_I2C_SPI_Pin | RES_Pin | LD4_Pin | LD3_Pin | LD5_Pin
			| LD7_Pin | LD9_Pin | LD10_Pin | LD8_Pin | LD6_Pin;
	GPIO_InitStruct.Mode = GPIO_MODE_OUTPUT_PP;
	GPIO_InitStruct.Pull = GPIO_NOPULL;
	GPIO_InitStruct.Speed = GPIO_SPEED_FREQ_LOW;
	HAL_GPIO_Init(GPIOE, &GPIO_InitStruct);

	/*Configure GPIO pin : B1_Pin */
	GPIO_InitStruct.Pin = B1_Pin;
	GPIO_InitStruct.Mode = GPIO_MODE_INPUT;
	GPIO_InitStruct.Pull = GPIO_NOPULL;
	HAL_GPIO_Init(B1_GPIO_Port, &GPIO_InitStruct);

	/*Configure GPIO pin : B2_Pin */
	GPIO_InitStruct.Pin = B2_Pin;
	GPIO_InitStruct.Mode = GPIO_MODE_IT_RISING_FALLING;
	GPIO_InitStruct.Pull = GPIO_PULLUP;
	HAL_GPIO_Init(B2_GPIO_Port, &GPIO_InitStruct);

	/*Configure GPIO pin : CS_Pin */
	GPIO_InitStruct.Pin = CS_Pin;
	GPIO_InitStruct.Mode = GPIO_MODE_OUTPUT_PP;
	GPIO_InitStruct.Pull = GPIO_NOPULL;
	GPIO_InitStruct.Speed = GPIO_SPEED_FREQ_LOW;
	HAL_GPIO_Init(CS_GPIO_Port, &GPIO_InitStruct);

	/*Configure GPIO pin : DC_Pin */
	GPIO_InitStruct.Pin = DC_Pin;
	GPIO_InitStruct.Mode = GPIO_MODE_OUTPUT_PP;
	GPIO_InitStruct.Pull = GPIO_NOPULL;
	GPIO_InitStruct.Speed = GPIO_SPEED_FREQ_LOW;
	HAL_GPIO_Init(DC_GPIO_Port, &GPIO_InitStruct);

	/*Configure GPIO pins : DM_Pin DP_Pin */
	GPIO_InitStruct.Pin = DM_Pin | DP_Pin;
	GPIO_InitStruct.Mode = GPIO_MODE_AF_PP;
	GPIO_InitStruct.Pull = GPIO_NOPULL;
	GPIO_InitStruct.Speed = GPIO_SPEED_FREQ_HIGH;
	GPIO_InitStruct.Alternate = GPIO_AF14_USB;
	HAL_GPIO_Init(GPIOA, &GPIO_InitStruct);

	/*Configure GPIO pin : PD6 */
	GPIO_InitStruct.Pin = GPIO_PIN_6;
	GPIO_InitStruct.Mode = GPIO_MODE_AF_PP;
	GPIO_InitStruct.Pull = GPIO_NOPULL;
	GPIO_InitStruct.Speed = GPIO_SPEED_FREQ_HIGH;
	GPIO_InitStruct.Alternate = GPIO_AF7_USART2;
	HAL_GPIO_Init(GPIOD, &GPIO_InitStruct);

	/*Configure GPIO pins : I2C1_SCL_Pin I2C1_SDA_Pin */
	GPIO_InitStruct.Pin = I2C1_SCL_Pin | I2C1_SDA_Pin;
	GPIO_InitStruct.Mode = GPIO_MODE_AF_OD;
	GPIO_InitStruct.Pull = GPIO_PULLUP;
	GPIO_InitStruct.Speed = GPIO_SPEED_FREQ_LOW;
	GPIO_InitStruct.Alternate = GPIO_AF4_I2C1;
	HAL_GPIO_Init(GPIOB, &GPIO_InitStruct);

	/* EXTI interrupt init*/
	HAL_NVIC_SetPriority(EXTI3_IRQn, 0, 0);
	HAL_NVIC_EnableIRQ(EXTI3_IRQn);

}

void _Error_Handler(char *file, int line) {
	while (1) {
	}
}

/************************ (C) COPYRIGHT STMicroelectronics *****END OF FILE****/
